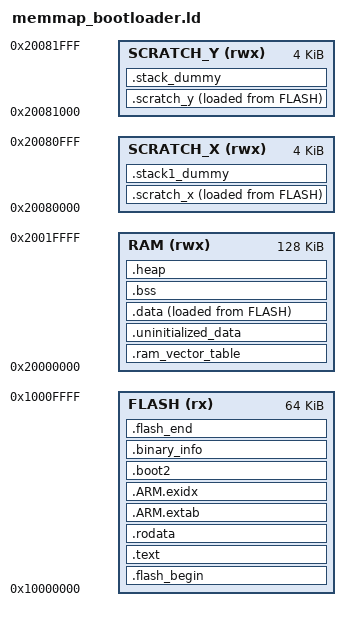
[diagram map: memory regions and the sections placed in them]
/* Linker script for bootloader / RP2350 test at XIP base 0x10000000.
   Based on the RP2350 default memmap from the Pico SDK.
   Merges RP2350 requirements (scratch_x, scratch_y, init arrays)
   with the custom flash base 0x10000000.
   Must fit in 64 KB.
*/

MEMORY
{
    FLASH(rx) : ORIGIN = 0x10000000, LENGTH = 64K
    RAM(rwx) : ORIGIN =  0x20000000, LENGTH = 128k
    SCRATCH_X(rwx) : ORIGIN = 0x20080000, LENGTH = 4k
    SCRATCH_Y(rwx) : ORIGIN = 0x20081000, LENGTH = 4k
}

ENTRY(_entry_point)

SECTIONS
{
    .flash_begin : {
        __flash_binary_start = .;
    } > FLASH

    .text : {
        __logical_binary_start = .;
        KEEP(*(.vectors))
        KEEP(*(.binary_info_header))
        __binary_info_header_end = .;
        KEEP(*(.embedded_block))
        __embedded_block_end = .;
        KEEP(*(.reset))
        *(.init)
        *(.text*)
        *(.fini)
        /* C++ constructors */
        *crtbegin.o(.ctors)
        *crtbegin?.o(.ctors)
        *(EXCLUDE_FILE(*crtend?.o *crtend.o) .ctors)
        *(SORT(.ctors.*))
        *(.ctors)
        *crtbegin.o(.dtors)
        *crtbegin?.o(.dtors)
        *(EXCLUDE_FILE(*crtend?.o *crtend.o) .dtors)
        *(SORT(.dtors.*))
        *(.dtors)
        . = ALIGN(4);
        PROVIDE_HIDDEN (__preinit_array_start = .);
        KEEP(*(SORT(.preinit_array.*)))
        KEEP(*(.preinit_array))
        PROVIDE_HIDDEN (__preinit_array_end = .);
        . = ALIGN(4);
        PROVIDE_HIDDEN (__init_array_start = .);
        KEEP(*(SORT(.init_array.*)))
        KEEP(*(.init_array))
        PROVIDE_HIDDEN (__init_array_end = .);
        . = ALIGN(4);
        PROVIDE_HIDDEN (__fini_array_start = .);
        *(SORT(.fini_array.*))
        *(.fini_array)
        PROVIDE_HIDDEN (__fini_array_end = .);
        *(.eh_frame*)
        . = ALIGN(4);
    } > FLASH

    .rodata : {
        *(.rodata*)
        *(.srodata*)
        . = ALIGN(4);
        *(SORT_BY_ALIGNMENT(SORT_BY_NAME(.flashdata*)))
        . = ALIGN(4);
    } > FLASH

    .ARM.extab : {
        *(.ARM.extab* .gnu.linkonce.armextab.*)
    } > FLASH

    __exidx_start = .;
    .ARM.exidx : {
        *(.ARM.exidx* .gnu.linkonce.armexidx.*)
    } > FLASH
    __exidx_end = .;

    /* boot2 (XIP setup function) — opcional, el BootROM NO lo llama.
       En RP2350 el BootROM hace XIP setup básico por sí solo.
       El orden correcto es vectors primero, boot2 después de .text. */
    .boot2 : {
        __boot2_start__ = .;
        KEEP(*(.boot2))
        __boot2_end__ = .;
    } > FLASH

    ASSERT(__boot2_end__ - __boot2_start__ <= 256,
        "ERROR: second stage bootloader must be no more than 256 bytes in size")

    . = ALIGN(4);
    __binary_info_start = .;
    .binary_info : {
        KEEP(*(.binary_info.keep.*))
        *(.binary_info.*)
    } > FLASH
    __binary_info_end = .;
    . = ALIGN(4);

    .ram_vector_table (NOLOAD): {
        *(.ram_vector_table)
    } > RAM

    .uninitialized_data (NOLOAD): {
        . = ALIGN(4);
        *(.uninitialized_data*)
    } > RAM

    .data : {
        __data_start__ = .;
        *(vtable)
        *(.time_critical*)
        *(.text*)
        . = ALIGN(4);
        *(.rodata*)
        . = ALIGN(4);
        *(.data*)
        *(.sdata*)
        . = ALIGN(4);
        *(.after_data.*)
        . = ALIGN(4);
        PROVIDE_HIDDEN (__mutex_array_start = .);
        KEEP(*(SORT(.mutex_array.*)))
        KEEP(*(.mutex_array))
        PROVIDE_HIDDEN (__mutex_array_end = .);
        *(.jcr)
        . = ALIGN(4);
    } > RAM AT> FLASH
    __data_end__ = .;
    __etext = LOADADDR(.data);

    .bss (NOLOAD) : {
        . = ALIGN(4);
        __bss_start__ = .;
        *(SORT_BY_ALIGNMENT(SORT_BY_NAME(.bss*)))
        *(COMMON)
        PROVIDE(__global_pointer$ = . + 2K);
        *(.sbss*)
        . = ALIGN(4);
        __bss_end__ = .;
    } > RAM

    .heap (NOLOAD): {
        __end__ = .;
        end = __end__;
        KEEP(*(.heap*))
    } > RAM
    __HeapLimit = ORIGIN(RAM) + LENGTH(RAM);

    .scratch_x : {
        __scratch_x_start__ = .;
        *(.scratch_x.*)
        . = ALIGN(4);
        __scratch_x_end__ = .;
    } > SCRATCH_X AT > FLASH
    __scratch_x_source__ = LOADADDR(.scratch_x);

    .scratch_y : {
        __scratch_y_start__ = .;
        *(.scratch_y.*)
        . = ALIGN(4);
        __scratch_y_end__ = .;
    } > SCRATCH_Y AT > FLASH
    __scratch_y_source__ = LOADADDR(.scratch_y);

    .stack1_dummy (NOLOAD): {
        *(.stack1*)
    } > SCRATCH_X

    .stack_dummy (NOLOAD): {
        KEEP(*(.stack*))
    } > SCRATCH_Y

    .flash_end : {
        KEEP(*(.embedded_end_block*))
        PROVIDE(__flash_binary_end = .);
    } > FLASH =0xaa

    __StackLimit = ORIGIN(RAM) + LENGTH(RAM);
    __StackOneTop = ORIGIN(SCRATCH_X) + LENGTH(SCRATCH_X);
    __StackTop = ORIGIN(SCRATCH_Y) + LENGTH(SCRATCH_Y);
    __StackOneBottom = __StackOneTop - SIZEOF(.stack1_dummy);
    __StackBottom = __StackTop - SIZEOF(.stack_dummy);
    PROVIDE(__stack = __StackTop);
    PROVIDE(__heap_start = __end__);
    PROVIDE(__heap_end = __HeapLimit);

    ASSERT(__binary_info_header_end - __logical_binary_start <= 1024,
        "Binary info must be in first 1024 bytes of the binary")
    ASSERT(__embedded_block_end - __logical_binary_start <= 4096,
        "Embedded block must be in first 4096 bytes of the binary")
    ASSERT(ORIGIN(FLASH) == 0x10000000, "bootloader must be at flash base")
    ASSERT(__flash_binary_end - __flash_binary_start <= 64K,
        "bootloader exceeds 64 KB limit")
}
